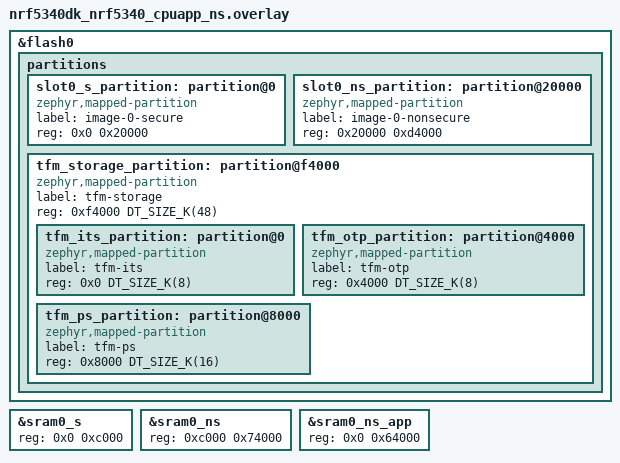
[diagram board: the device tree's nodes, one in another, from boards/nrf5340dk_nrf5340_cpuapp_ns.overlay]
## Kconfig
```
#
# Copyright (c) 2025 Nordic Semiconductor ASA
#
# SPDX-License-Identifier: LicenseRef-Nordic-5-Clause
#

menu "Wi-Fi Fund Lesson 5 Exercise 2"

config HTTP_SAMPLE_HOSTNAME
	string "HTTP server hostname"
	default "rest.nordicsemi.academy"

# STEP 3 - Change the default port if TLS is enabled
config HTTP_SAMPLE_PORT
    string "HTTP server port"
    default "80"

endmenu

source "Kconfig.zephyr"
```

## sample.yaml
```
sample:
  description: Wi-Fi Fundamentals Course by Nordic Developer Academy (https://academy.nordicsemi.com/)
  name: Wi-Fi Fundamentals Course - Lesson 5 Exercise 2 
  
common: 
    sysbuild: true
    build_only: true
    skip: true
    
tests:
  wifi_fund.l5.e2.nrf5340dk: 
    extra_args: SHIELD=nrf7002ek
    integration_platforms: 
    - nrf5340dk/nrf5340/cpuapp/ns
    - nrf5340dk/nrf5340/cpuapp
    platform_allow:
      - nrf5340dk/nrf5340/cpuapp/ns
      - nrf5340dk/nrf5340/cpuapp
  
  wifi_fund.l5.e2.nrf7002dk:
    integration_platforms: 
    - nrf7002dk/nrf5340/cpuapp/ns
    - nrf7002dk/nrf5340/cpuapp
    platform_allow:
      - nrf7002dk/nrf5340/cpuapp/ns
      - nrf7002dk/nrf5340/cpuapp
```

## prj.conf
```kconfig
#
# Copyright (c) 2023 Nordic Semiconductor ASA
#
# SPDX-License-Identifier: LicenseRef-Nordic-5-Clause
#

# Wi-Fi
CONFIG_WIFI=y
CONFIG_WIFI_NM_WPA_SUPPLICANT=y

CONFIG_NRF70_RX_NUM_BUFS=16
CONFIG_NRF70_MAX_TX_AGGREGATION=4

# Wi-Fi credentials
CONFIG_WIFI_CREDENTIALS=y
CONFIG_WIFI_CREDENTIALS_STATIC=n

# Networking Management API
CONFIG_NET_MGMT=y
CONFIG_NET_MGMT_EVENT=y
CONFIG_NET_MGMT_EVENT_INFO=y
CONFIG_NET_CONNECTION_MANAGER=y
CONFIG_NET_CONNECTION_MANAGER_MONITOR_STACK_SIZE=5200
CONFIG_L2_WIFI_CONNECTIVITY=y

# Support for shell commands
CONFIG_SHELL=y
CONFIG_NET_L2_WIFI_SHELL=y
CONFIG_WIFI_CREDENTIALS_SHELL=y
CONFIG_SHELL_STACK_SIZE=5200

# Logging
CONFIG_LOG=y

# DK library
CONFIG_DK_LIBRARY=y

# System settings
CONFIG_NEWLIB_LIBC=y
CONFIG_NEWLIB_LIBC_NANO=n

# Networking
CONFIG_NETWORKING=y
CONFIG_NET_SOCKETS=y
CONFIG_NET_L2_ETHERNET=y
CONFIG_NET_L2_ETHERNET=y
CONFIG_NET_IPV4=y
CONFIG_NET_IPV6=y
CONFIG_NET_TCP=y
CONFIG_NET_DHCPV4=y
CONFIG_DNS_RESOLVER=y
CONFIG_NET_SOCKETS_DNS_TIMEOUT=30000

# TLS
# STEP 1.1 - Enable the TLS library and security relevant configurations

# STEP 1.2 - Enable TLS credentials library and set backend

# STEP 1.3 - Enable mbedTLS relevant configurations 

# Memory
CONFIG_SYSTEM_WORKQUEUE_STACK_SIZE=4096
CONFIG_MAIN_STACK_SIZE=5200



# Configure network parameters
CONFIG_NET_TC_TX_COUNT=0
CONFIG_NET_BUF_TX_COUNT=16
CONFIG_NET_BUF_RX_COUNT=16
CONFIG_NET_PKT_TX_COUNT=14
CONFIG_NET_PKT_RX_COUNT=14
CONFIG_NET_TX_STACK_SIZE=4096
CONFIG_NET_RX_STACK_SIZE=4096
CONFIG_NET_BUF_FIXED_DATA_SIZE=y
CONFIG_NET_BUF_DATA_SIZE=256
CONFIG_NET_TCP_WORKQ_STACK_SIZE=2048

# HTTP
CONFIG_HTTP_CLIENT=y
```

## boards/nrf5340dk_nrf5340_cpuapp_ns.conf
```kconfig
CONFIG_WIFI_CREDENTIALS_BACKEND_PSA=y
CONFIG_TFM_PROFILE_TYPE_SMALL=y
# STEP 1.4 - Increase the mbedTLS heap 
CONFIG_MBEDTLS_HEAP_SIZE=16384
```

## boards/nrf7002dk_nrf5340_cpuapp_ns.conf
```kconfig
# UART1 is used for TF-M logging should be disabled
CONFIG_TFM_SECURE_UART=n
CONFIG_TFM_LOG_LEVEL_SILENCE=y

CONFIG_WIFI_CREDENTIALS_BACKEND_PSA=y
CONFIG_TFM_PROFILE_TYPE_SMALL=y
# STEP 1.4 - Increase the mbedTLS heap 
CONFIG_MBEDTLS_HEAP_SIZE=16384
```

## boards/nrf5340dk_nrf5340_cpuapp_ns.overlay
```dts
/*
 * Copyright (c) 2026 Nordic Semiconductor ASA
 *
 * SPDX-License-Identifier: LicenseRef-Nordic-5-Clause
 */

/delete-node/ &boot_partition;
/delete-node/ &slot0_partition;
/delete-node/ &slot1_partition;
/delete-node/ &tfm_its_partition;
/delete-node/ &tfm_otp_partition;
/delete-node/ &tfm_ps_partition;
/delete-node/ &storage_partition;

&flash0 {
	partitions {
		slot0_s_partition: partition@0 {
			compatible = "zephyr,mapped-partition";
			label = "image-0-secure";
			reg = <0x0 0x20000>;
		};

		slot0_ns_partition: partition@20000 {
			compatible = "zephyr,mapped-partition";
			label = "image-0-nonsecure";
			reg = <0x20000 0xd4000>;
		};

		tfm_storage_partition: partition@f4000 {
			compatible = "zephyr,mapped-partition";
			label = "tfm-storage";
			reg = <0xf4000 DT_SIZE_K(48)>;
			ranges = <0x0 0xf4000 DT_SIZE_K(48)>;
			#address-cells = <1>;
			#size-cells = <1>;

			tfm_its_partition: partition@0 {
				compatible = "zephyr,mapped-partition";
				label = "tfm-its";
				reg = <0x0 DT_SIZE_K(8)>;
			};

			tfm_otp_partition: partition@4000 {
				compatible = "zephyr,mapped-partition";
				label = "tfm-otp";
				reg = <0x4000 DT_SIZE_K(8)>;
			};

			tfm_ps_partition: partition@8000 {
				compatible = "zephyr,mapped-partition";
				label = "tfm-ps";
				reg = <0x8000 DT_SIZE_K(16)>;
			};
		};
	};
};

&sram0_s {
	reg = <0x0 0xc000>;
};

&sram0_ns {
	reg = <0xc000 0x74000>;
	ranges = <0x0 0xc000 0x74000>;
};

&sram0_ns_app {
	reg = <0x0 0x64000>;
};
```

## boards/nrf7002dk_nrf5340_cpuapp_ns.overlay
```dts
/*
 * Copyright (c) 2026 Nordic Semiconductor ASA
 *
 * SPDX-License-Identifier: LicenseRef-Nordic-5-Clause
 */

/delete-node/ &boot_partition;
/delete-node/ &slot0_partition;
/delete-node/ &slot1_partition;
/delete-node/ &tfm_its_partition;
/delete-node/ &tfm_otp_partition;
/delete-node/ &tfm_ps_partition;

&flash0 {
	partitions {
		slot0_s_partition: partition@0 {
			compatible = "zephyr,mapped-partition";
			label = "image-0-secure";
			reg = <0x0 0x20000>;
		};

		slot0_ns_partition: partition@20000 {
			compatible = "zephyr,mapped-partition";
			label = "image-0-nonsecure";
			reg = <0x20000 0xd4000>;
		};

		tfm_storage_partition: partition@f4000 {
			compatible = "zephyr,mapped-partition";
			label = "tfm-storage";
			reg = <0xf4000 DT_SIZE_K(48)>;
			ranges = <0x0 0xf4000 DT_SIZE_K(48)>;
			#address-cells = <1>;
			#size-cells = <1>;

			tfm_its_partition: partition@0 {
				compatible = "zephyr,mapped-partition";
				label = "tfm-its";
				reg = <0x0 DT_SIZE_K(8)>;
			};

			tfm_otp_partition: partition@4000 {
				compatible = "zephyr,mapped-partition";
				label = "tfm-otp";
				reg = <0x4000 DT_SIZE_K(8)>;
			};

			tfm_ps_partition: partition@8000 {
				compatible = "zephyr,mapped-partition";
				label = "tfm-ps";
				reg = <0x8000 DT_SIZE_K(16)>;
			};
		};
	};
};

&sram0_s {
	reg = <0x0 0xc000>;
};

&sram0_ns {
	reg = <0xc000 0x74000>;
	ranges = <0x0 0xc000 0x74000>;
};

&sram0_ns_app {
	reg = <0x0 0x64000>;
};
```

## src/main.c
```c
/*
 * Copyright (c) 2023 Nordic Semiconductor ASA
 *
 * SPDX-License-Identifier: LicenseRef-Nordic-5-Clause
 */

#include <errno.h>
#include <stddef.h>
#include <string.h>
#include <stdio.h>
#include <zephyr/kernel.h>
#include <zephyr/types.h>
#include <zephyr/logging/log.h>

#include <dk_buttons_and_leds.h>

#include <zephyr/net/net_mgmt.h>
#include <zephyr/net/wifi_mgmt.h>
#include <zephyr/net/wifi_credentials.h>
#include <zephyr/net/socket.h>
#include <zephyr/net/http/client.h>

/* STEP 1.5 - Include the header file for the TLS credentials library */


LOG_MODULE_REGISTER(Lesson5_Exercise2, LOG_LEVEL_INF);

#define EVENT_MASK (NET_EVENT_L4_CONNECTED | NET_EVENT_L4_DISCONNECTED)

/* STEP 4.1 - Define a macro for the credentials security tag */


#define RECV_BUF_SIZE  2048
#define CLIENT_ID_SIZE 36

static char recv_buf[RECV_BUF_SIZE];
static char client_id_buf[CLIENT_ID_SIZE + 2];

static int counter = 0;

static int sock;
static struct sockaddr_storage server;

static struct net_mgmt_event_callback mgmt_cb;
static bool connected;
static K_SEM_DEFINE(run_app, 0, 1);

/* STEP 2.3 - Include the certificate */



static void net_mgmt_event_handler(struct net_mgmt_event_callback *cb, uint64_t mgmt_event,
				   struct net_if *iface)
{
	if ((mgmt_event & EVENT_MASK) != mgmt_event) {
		return;
	}
	if (mgmt_event == NET_EVENT_L4_CONNECTED) {
		LOG_INF("Network connected");
		connected = true;
		dk_set_led_on(DK_LED1);
		k_sem_give(&run_app);
		return;
	}
	if (mgmt_event == NET_EVENT_L4_DISCONNECTED) {
		if (connected == false) {
			LOG_INF("Waiting for network to be connected");
		} else {
			dk_set_led_off(DK_LED1);
			LOG_INF("Network disconnected");
			connected = false;
		}
		k_sem_reset(&run_app);
		return;
	}
}

static int server_resolve(void)
{
	int err;
	struct zsock_addrinfo *result;
	struct zsock_addrinfo hints = {.ai_family = AF_INET, .ai_socktype = SOCK_STREAM};

	err = zsock_getaddrinfo(CONFIG_HTTP_SAMPLE_HOSTNAME, CONFIG_HTTP_SAMPLE_PORT, &hints, &result);
	if (err != 0) {
		LOG_ERR("getaddrinfo failed, err: %d, %s", err, zsock_gai_strerror(err));
		return -EIO;
	}

	if (result == NULL) {
		LOG_ERR("Error, address not found");
		return -ENOENT;
	}

	struct sockaddr_in *server4 = ((struct sockaddr_in *)&server);
	server4->sin_addr.s_addr = ((struct sockaddr_in *)result->ai_addr)->sin_addr.s_addr;
	server4->sin_family = AF_INET;
	server4->sin_port = ((struct sockaddr_in *)result->ai_addr)->sin_port;

	char ipv4_addr[NET_IPV4_ADDR_LEN];
	zsock_inet_ntop(AF_INET, &server4->sin_addr.s_addr, ipv4_addr, sizeof(ipv4_addr));
	LOG_INF("IPv4 address of HTTP server found %s", ipv4_addr);

	zsock_freeaddrinfo(result);

	return 0;
}

static int setup_credentials(void)
{
	LOG_INF("Provisioning server certificate");
	/* STEP 4.2 - Provision the credential to the device */


	return err;
}

static int server_connect(void)
{
	int err;
	sock = zsock_socket(AF_INET, SOCK_STREAM, IPPROTO_TLS_1_2);
	if (sock < 0) {
		LOG_ERR("Failed to set up HTTPS socket, err: %d, %s", errno, strerror(errno));
		return -errno;
	}

	/* STEP 5.1 - Configure the socket with the security tag for the certificate */

	/* STEP 5.2 - Configure the socket with the hostname of the HTTP server */


	err = zsock_connect(sock, (struct sockaddr *)&server, sizeof(struct sockaddr_in));
	if (err < 0) {
		LOG_ERR("Connecting to server failed, err: %d, %s", errno, strerror(errno));
		return -errno;
	}

	LOG_INF("Connected to server");
	return 0;
}

static int response_cb(struct http_response *rsp, enum http_final_call final_data, void *user_data)
{
	LOG_INF("Response status: %s", rsp->http_status);

	if (rsp->body_frag_len > 0) {
		char body_buf[rsp->body_frag_len];
		strncpy(body_buf, rsp->body_frag_start, rsp->body_frag_len);
		body_buf[rsp->body_frag_len] = '\0';
		LOG_INF("Received: %s", body_buf);
	}

	LOG_INF("Closing socket: %d", sock);
	zsock_close(sock);
	return 0;
}

static int client_id_cb(struct http_response *rsp, enum http_final_call final_data,
			 void *user_data)
{
	LOG_INF("Response status: %s", rsp->http_status);

	char client_id_buf_tmp[CLIENT_ID_SIZE + 1];
	strncpy(client_id_buf_tmp, rsp->body_frag_start, CLIENT_ID_SIZE);
	client_id_buf_tmp[CLIENT_ID_SIZE] = '\0';
	client_id_buf[0] = '/';
	strcat(client_id_buf, client_id_buf_tmp);

	LOG_INF("Successfully acquired client ID: %s", client_id_buf);
	LOG_INF("Closing socket: %d", sock);
	zsock_close(sock);
	return 0;
}

static int client_http_put(void)
{
	int err = 0;
	int bytes_written;
	const char *headers[] = {"Connection: close\r\n", NULL};

	struct http_request req;
	memset(&req, 0, sizeof(req));

	char buffer[12] = {0};
	bytes_written = snprintf(buffer, 12, "%d", counter);
	if (bytes_written < 0) {
		LOG_INF("Unable to write to buffer, err: %d", bytes_written);
		return bytes_written;
	}

	req.header_fields = headers;
	req.method = HTTP_PUT;
	req.url = client_id_buf;
	req.host = CONFIG_HTTP_SAMPLE_HOSTNAME;
	req.protocol = "HTTP/1.1";
	req.payload = buffer;
	req.payload_len = bytes_written;
	req.response = response_cb;
	req.recv_buf = recv_buf;
	req.recv_buf_len = sizeof(recv_buf);

	LOG_INF("HTTP PUT request: %s", buffer);
	err = http_client_req(sock, &req, 5000, NULL);
	if (err < 0) {
		LOG_ERR("Failed to send HTTP PUT request %s, err: %d", buffer, err);
	}

	return err;
}

static int client_http_get(void)
{
	int err = 0;
	const char *headers[] = {"Connection: close\r\n", NULL};

	struct http_request req;
	memset(&req, 0, sizeof(req));

	req.header_fields = headers;
	req.method = HTTP_GET;
	req.url = client_id_buf;
	req.host = CONFIG_HTTP_SAMPLE_HOSTNAME;
	req.protocol = "HTTP/1.1";
	req.response = response_cb;
	req.recv_buf = recv_buf;
	req.recv_buf_len = sizeof(recv_buf);

	LOG_INF("HTTP GET request");
	err = http_client_req(sock, &req, 5000, NULL);
	if (err < 0) {
		LOG_ERR("Failed to send HTTP GET request, err: %d", err);
	}

	return err;
}

static int client_get_new_id(void)
{
	int err = 0;

	struct http_request req;
	memset(&req, 0, sizeof(req));

	const char *headers[] = {"Connection: close\r\n", NULL};
	req.header_fields = headers;
	req.method = HTTP_POST;
	req.url = "/new";
	req.host = CONFIG_HTTP_SAMPLE_HOSTNAME;
	req.protocol = "HTTP/1.1";
	req.response = client_id_cb;
	req.recv_buf = recv_buf;
	req.recv_buf_len = sizeof(recv_buf);

	LOG_INF("HTTP POST request");
	err = http_client_req(sock, &req, 5000, NULL);
	if (err < 0) {
		LOG_ERR("Failed to send HTTP POST request, err: %d", err);
	}
	return err;
}

static void button_handler(uint32_t button_state, uint32_t has_changed)
{
	if (has_changed & DK_BTN1_MSK && button_state & DK_BTN1_MSK) {
		if (server_connect() >= 0) {
			client_http_put();
			counter++;
		}
	} else if (has_changed & DK_BTN2_MSK && button_state & DK_BTN2_MSK) {
		if (server_connect() >= 0) {
			client_http_get();
		}
	}
}

int main(void)
{

	if (dk_leds_init() != 0) {
		LOG_ERR("Failed to initialize the LED library");
	}

	/* Sleep to allow initialization of Wi-Fi driver */
	k_sleep(K_SECONDS(1));

	net_mgmt_init_event_callback(&mgmt_cb, net_mgmt_event_handler, EVENT_MASK);
	net_mgmt_add_event_callback(&mgmt_cb);

	LOG_INF("Waiting to connect to Wi-Fi");
	k_sem_take(&run_app, K_FOREVER);

	if (dk_buttons_init(button_handler) != 0) {
		LOG_ERR("Failed to initialize the buttons library");
	}
	if (server_resolve() != 0) {
		LOG_ERR("Failed to resolve server name");
		return 0;
	}

	if (setup_credentials() != 0) {
		LOG_ERR("Setup credentials failed");
	}

	LOG_INF("Connecting to %s:%s", CONFIG_HTTP_SAMPLE_HOSTNAME, CONFIG_HTTP_SAMPLE_PORT);
	if (server_connect() != 0) {
		LOG_ERR("Failed to connect to server");
		return 0;
	}

	if (client_get_new_id() < 0) {
		LOG_ERR("Failed to get client ID");
		return 0;
	}

	if (server_connect() >= 0) {
		client_http_put();
		counter++;
	}

	return 0;
}
```
